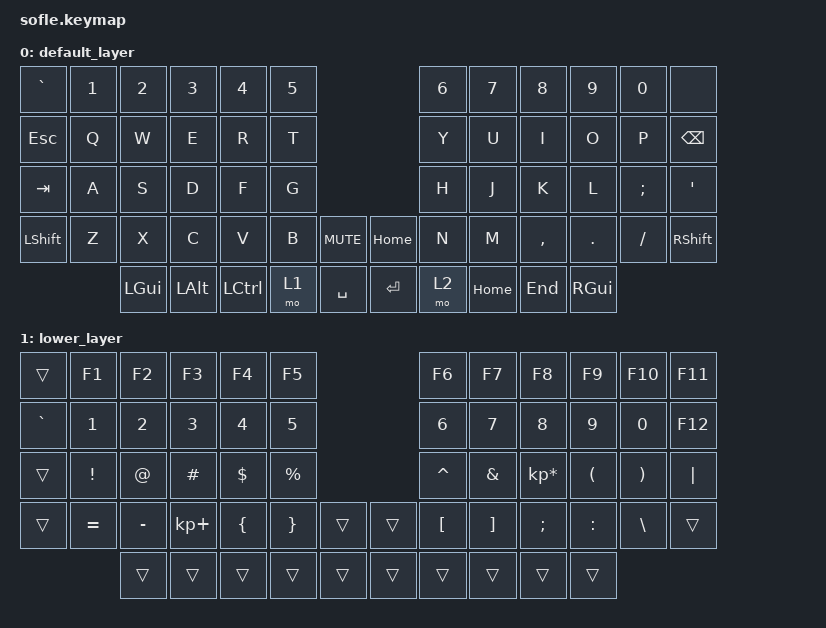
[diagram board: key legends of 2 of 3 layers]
/*
 * Copyright (c) 2020 The ZMK Contributors
 *
 * SPDX-License-Identifier: MIT
 */

#include <behaviors.dtsi>
#include <dt-bindings/zmk/keys.h>
#include <dt-bindings/zmk/bt.h>
#include <dt-bindings/zmk/mouse.h>

/ {
    keymap {
        compatible = "zmk,keymap";

        default_layer {
// ------------------------------------------------------------------------------------------------------------
// |  `    |  1  |  2  |  3   |  4   |  5   |                   |  6   |  7    |  8    |  9   |   0   |       |
// |  ESC  |  Q  |  W  |  E   |  R   |  T   |                   |  Y   |  U    |  I    |  O   |   P   | BKSPC |
// |  TAB  |  A  |  S  |  D   |  F   |  G   |                   |  H   |  J    |  K    |  L   |   ;   |   '   |
// | SHIFT |  Z  |  X  |  C   |  V   |  B   |  MUTE  |  | HOME  |  N   |  M    |  ,    |  .   |   /   | SHIFT |
//               | GUI | ALT  | CTRL | LOWER|  ENTER |  | SPACE | RAISE| HOME  | END   | GUI  |
            bindings = <
&kp GRAVE &kp N1 &kp N2   &kp N3   &kp N4    &kp N5                      &kp N6 &kp N7    &kp N8    &kp N9   &kp N0   &none
&kp ESC   &kp Q  &kp W    &kp E    &kp R     &kp T                       &kp Y  &kp U     &kp I     &kp O    &kp P    &kp BSPC
&kp TAB   &kp A  &kp S    &kp D    &kp F     &kp G                       &kp H  &kp J     &kp K     &kp L    &kp SEMI &kp SQT
&kp LSHFT &kp Z  &kp X    &kp C    &kp V     &kp B  &kp C_MUTE &kp HOME &kp N  &kp M     &kp COMMA &kp DOT  &kp FSLH &kp RSHFT
                 &kp LGUI &kp LALT &kp LCTRL &mo 1  &kp SPACE    &kp RET &mo 2  &kp HOME &kp END  &kp RGUI
            >;

            sensor-bindings = <&inc_dec_kp C_VOL_UP C_VOL_DN &inc_dec_kp PG_UP PG_DN>;
        };

        lower_layer {
// TODO: Some binds are waiting for shifted keycode support.
// ------------------------------------------------------------------------------------------------------------
// |       |  F1 |  F2 |  F3  |  F4  |  F5  |                   |  F6  |  F7   |  F8   |  F9  |  F10  |  F11  |
// | `     |   1 |   2 |   3  |   4  |   5  |                   |   6  |   7   |   8   |   9  |    0  |  F12  |
// |       |  !  |  @  |  #   |  $   |  %   |                   |  ^   |  &    |  *    |  (   |   )   |   |   |
// |       |  =  |  -  |  +   |  {   |  }   |        |  |       |  [   |  ]    |  ;    |  :   |   \   |       |
//               |     |      |      |      |        |  |       |      |       |       |      |
            bindings = <
&trans    &kp F1    &kp F2    &kp F3      &kp F4    &kp F5                    &kp F6    &kp F7   &kp F8          &kp F9    &kp F10   &kp F11
&kp GRAVE &kp N1    &kp N2    &kp N3      &kp N4    &kp N5                    &kp N6    &kp N7   &kp N8          &kp N9    &kp N0    &kp F12
&trans    &kp EXCL  &kp AT    &kp HASH    &kp DLLR  &kp PRCNT                 &kp CARET &kp AMPS &kp KP_MULTIPLY &kp LPAR  &kp RPAR  &kp PIPE
&trans    &kp EQUAL &kp MINUS &kp KP_PLUS &kp LBRC  &kp RBRC  &trans   &trans &kp LBKT  &kp RBKT &kp SEMI        &kp COLON &kp BSLH  &trans
                    &trans    &trans      &trans    &trans    &trans   &trans &trans    &trans   &trans          &trans
            >;

            sensor-bindings = <&inc_dec_kp C_VOL_UP C_VOL_DN &inc_dec_kp PG_UP PG_DN>;
        };

        raise_layer {
// ------------------------------------------------------------------------------------------------------------
// |BTCLR| BT1  | BT2  |  BT3  |  BT4  |  BT5 |                |      | PGDN | PGUP  |      |       |       |
// |     | INS  | PSCR | GUI   | LCLK  | RCLK |                |  <-  |   v  |   ^   |  ->  |  del  |  BSPC |
// |     | ALT  | CTRL | SHIFT | MCLK  | CAPS |                |  <m- |   mv |   m^  |  -m> | scrUp | scrDw |
// |     | UNDO | CUT  | COPY  | PASTE |      |      |  |      |      |      |       |      |       |       |
//              |      |       |       |      |      |  |      |      |      |       |      |
            bindings = <
&bt BT_CLR &bt BT_SEL 0 &bt BT_SEL 1 &bt BT_SEL 2 &bt BT_SEL 3 &bt BT_SEL 4             &trans          &kp PG_DN       &kp PG_UP       &trans          &trans          &trans
&trans     &kp INS      &kp PSCRN    &kp K_CMENU  &mkp LCLK    &mkp RCLK                &kp LEFT        &kp DOWN        &kp UP          &kp RIGHT       &kp DEL         &kp BSPC
&trans     &kp LALT     &kp LCTRL    &kp LSHFT    &mkp MCLK    &kp CLCK                 &mmv MOVE_LEFT  &mmv MOVE_DOWN  &mmv MOVE_UP    &mmv MOVE_RIGHT &mwh SCROLL_DOWN  &mwh SCROLL_UP
&trans     &kp K_UNDO   &kp K_CUT    &kp K_COPY   &kp K_PASTE  &trans  &trans   &trans  &trans          &trans          &trans          &trans          &trans
                        &trans       &trans       &trans       &trans  &trans   &trans  &trans          &trans          &trans          &trans
            >;

            sensor-bindings = <&inc_dec_kp C_VOL_UP C_VOL_DN &inc_dec_kp PG_UP PG_DN>;
        };
    };
};
